# ESP32-C61 register map
Vendor: ESPRESSIF SYSTEMS (SHANGHAI) CO., LTD.; Series: ESP32 C-Series; File version: 1
CPU: RV32IMAC r0p0, little endian, no MPU, no FPU, 0 interrupt priority bits
Address unit: 32 bits
Registers are 32-bit, read-write, reset 0x0 unless marked. A register's access mark holds for its fields unless they carry their own. Offsets are from the block's base; [hi:lo] are bit positions; {n}, {i} and the like mark numbered series.

## AHB_DMA — AHB_DMA Peripheral
Base 0x60080000
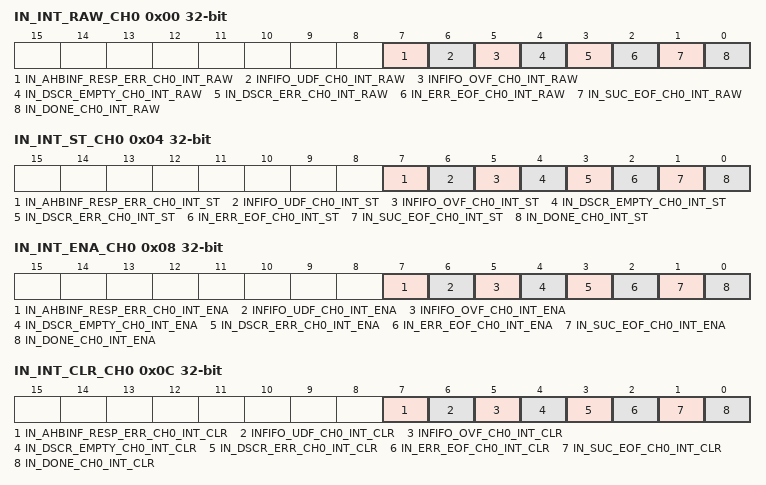
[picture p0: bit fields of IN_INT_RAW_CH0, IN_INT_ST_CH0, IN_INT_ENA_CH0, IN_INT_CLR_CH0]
0x00 IN_INT_RAW_CH0 — Raw interrupt status of RX channel 0
  [7] IN_AHBINF_RESP_ERR_CH0_INT_RAW — The raw interrupt status of AHB_DMA_IN_RESP_ERR_CH0_INT
  [6] INFIFO_UDF_CH0_INT_RAW — The raw interrupt status of AHB_DMA_INFIFO_UDF_CH0_INT
  [5] INFIFO_OVF_CH0_INT_RAW — The raw interrupt status of AHB_DMA_INFIFO_OVF_CH0_INT
  [4] IN_DSCR_EMPTY_CH0_INT_RAW — The raw interrupt status of AHB_DMA_IN_DSCR_EMPTY_CH0_INT
  [3] IN_DSCR_ERR_CH0_INT_RAW — The raw interrupt status of AHB_DMA_IN_DSCR_ERR_CH0_INT
  [2] IN_ERR_EOF_CH0_INT_RAW — The raw interrupt status of AHB_DMA_IN_ERR_EOF_CH0_INT
  [1] IN_SUC_EOF_CH0_INT_RAW — The raw interrupt status of AHB_DMA_IN_SUC_EOF_CH0_INT
  [0] IN_DONE_CH0_INT_RAW — The raw interrupt status of AHB_DMA_IN_DONE_CH0_INT
0x04 IN_INT_ST_CH0 ro — Masked interrupt status of RX channel 0
  [7] IN_AHBINF_RESP_ERR_CH0_INT_ST — The masked interrupt status of AHB_DMA_IN_RESP_ERR_CH0_INT
  [6] INFIFO_UDF_CH0_INT_ST — The masked interrupt status of AHB_DMA_INFIFO_UDF_CH0_INT
  [5] INFIFO_OVF_CH0_INT_ST — The masked interrupt status of AHB_DMA_INFIFO_OVF_CH0_INT
  [4] IN_DSCR_EMPTY_CH0_INT_ST — The masked interrupt status of AHB_DMA_IN_DSCR_EMPTY_CH0_INT
  [3] IN_DSCR_ERR_CH0_INT_ST — The masked interrupt status of AHB_DMA_IN_DSCR_ERR_CH0_INT
  [2] IN_ERR_EOF_CH0_INT_ST — The masked interrupt status of AHB_DMA_IN_ERR_EOF_CH0_INT
  [1] IN_SUC_EOF_CH0_INT_ST — The masked interrupt status of AHB_DMA_IN_SUC_EOF_CH0_INT
  [0] IN_DONE_CH0_INT_ST — The masked interrupt status of AHB_DMA_IN_DONE_CH0_INT
0x08 IN_INT_ENA_CH0 — Interrupt enable bits of RX channel 0
  [7] IN_AHBINF_RESP_ERR_CH0_INT_ENA — Write 1 to enable AHB_DMA_IN_RESP_ERR_CH0_INT
  [6] INFIFO_UDF_CH0_INT_ENA — Write 1 to enable AHB_DMA_INFIFO_UDF_CH0_INT
  [5] INFIFO_OVF_CH0_INT_ENA — Write 1 to enable AHB_DMA_INFIFO_OVF_CH0_INT
  [4] IN_DSCR_EMPTY_CH0_INT_ENA — Write 1 to enable AHB_DMA_IN_DSCR_EMPTY_CH0_INT
  [3] IN_DSCR_ERR_CH0_INT_ENA — Write 1 to enable AHB_DMA_IN_DSCR_ERR_CH0_INT
  [2] IN_ERR_EOF_CH0_INT_ENA — Write 1 to enable AHB_DMA_IN_ERR_EOF_CH0_INT
  [1] IN_SUC_EOF_CH0_INT_ENA — Write 1 to enable AHB_DMA_IN_SUC_EOF_CH0_INT
  [0] IN_DONE_CH0_INT_ENA — Write 1 to enable AHB_DMA_IN_DONE_CH0_INT
0x0C IN_INT_CLR_CH0 wo — Interrupt clear bits of RX channel 0
  [7] IN_AHBINF_RESP_ERR_CH0_INT_CLR — Write 1 to clear AHB_DMA_IN_RESP_ERR_CH0_INT
  [6] INFIFO_UDF_CH0_INT_CLR — Write 1 to clear AHB_DMA_INFIFO_UDF_CH0_INT
  [5] INFIFO_OVF_CH0_INT_CLR — Write 1 to clear AHB_DMA_INFIFO_OVF_CH0_INT
  [4] IN_DSCR_EMPTY_CH0_INT_CLR — Write 1 to clear AHB_DMA_IN_DSCR_EMPTY_CH0_INT
  [3] IN_DSCR_ERR_CH0_INT_CLR — Write 1 to clear AHB_DMA_IN_DSCR_ERR_CH0_INT
  [2] IN_ERR_EOF_CH0_INT_CLR — Write 1 to clear AHB_DMA_IN_ERR_EOF_CH0_INT
  [1] IN_SUC_EOF_CH0_INT_CLR — Write 1 to clear AHB_DMA_IN_SUC_EOF_CH0_INT
  [0] IN_DONE_CH0_INT_CLR — Write 1 to clear AHB_DMA_IN_DONE_CH0_INT
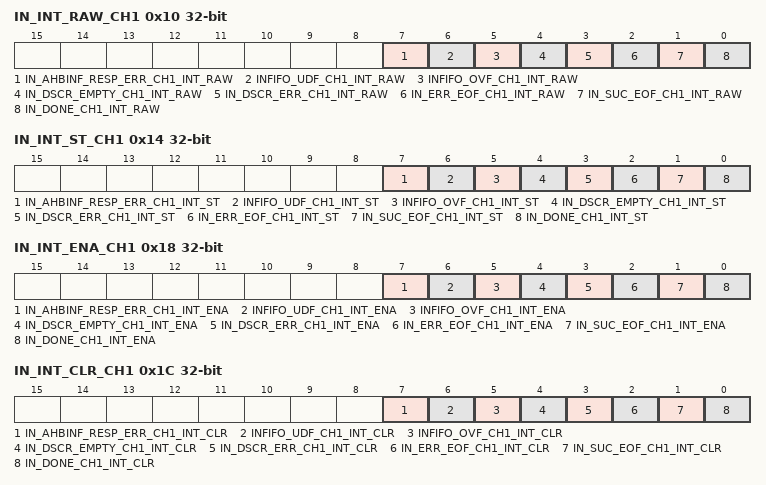
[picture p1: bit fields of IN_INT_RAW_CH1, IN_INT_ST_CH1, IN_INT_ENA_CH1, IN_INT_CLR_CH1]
0x10 IN_INT_RAW_CH1 — Raw interrupt status of RX channel 1
  [7] IN_AHBINF_RESP_ERR_CH1_INT_RAW — The raw interrupt status of AHB_DMA_IN_RESP_ERR_CH1_INT
  [6] INFIFO_UDF_CH1_INT_RAW — The raw interrupt status of AHB_DMA_INFIFO_UDF_CH1_INT
  [5] INFIFO_OVF_CH1_INT_RAW — The raw interrupt status of AHB_DMA_INFIFO_OVF_CH1_INT
  [4] IN_DSCR_EMPTY_CH1_INT_RAW — The raw interrupt status of AHB_DMA_IN_DSCR_EMPTY_CH1_INT
  [3] IN_DSCR_ERR_CH1_INT_RAW — The raw interrupt status of AHB_DMA_IN_DSCR_ERR_CH1_INT
  [2] IN_ERR_EOF_CH1_INT_RAW — The raw interrupt status of AHB_DMA_IN_ERR_EOF_CH1_INT
  [1] IN_SUC_EOF_CH1_INT_RAW — The raw interrupt status of AHB_DMA_IN_SUC_EOF_CH1_INT
  [0] IN_DONE_CH1_INT_RAW — The raw interrupt status of AHB_DMA_IN_DONE_CH1_INT
0x14 IN_INT_ST_CH1 ro — Masked interrupt status of RX channel 1
  [7] IN_AHBINF_RESP_ERR_CH1_INT_ST — The masked interrupt status of AHB_DMA_IN_RESP_ERR_CH1_INT
  [6] INFIFO_UDF_CH1_INT_ST — The masked interrupt status of AHB_DMA_INFIFO_UDF_CH1_INT
  [5] INFIFO_OVF_CH1_INT_ST — The masked interrupt status of AHB_DMA_INFIFO_OVF_CH1_INT
  [4] IN_DSCR_EMPTY_CH1_INT_ST — The masked interrupt status of AHB_DMA_IN_DSCR_EMPTY_CH1_INT
  [3] IN_DSCR_ERR_CH1_INT_ST — The masked interrupt status of AHB_DMA_IN_DSCR_ERR_CH1_INT
  [2] IN_ERR_EOF_CH1_INT_ST — The masked interrupt status of AHB_DMA_IN_ERR_EOF_CH1_INT
  [1] IN_SUC_EOF_CH1_INT_ST — The masked interrupt status of AHB_DMA_IN_SUC_EOF_CH1_INT
  [0] IN_DONE_CH1_INT_ST — The masked interrupt status of AHB_DMA_IN_DONE_CH1_INT
0x18 IN_INT_ENA_CH1 — Interrupt enable bits of RX channel 1
  [7] IN_AHBINF_RESP_ERR_CH1_INT_ENA — Write 1 to enable AHB_DMA_IN_RESP_ERR_CH1_INT
  [6] INFIFO_UDF_CH1_INT_ENA — Write 1 to enable AHB_DMA_INFIFO_UDF_CH1_INT
  [5] INFIFO_OVF_CH1_INT_ENA — Write 1 to enable AHB_DMA_INFIFO_OVF_CH1_INT
  [4] IN_DSCR_EMPTY_CH1_INT_ENA — Write 1 to enable AHB_DMA_IN_DSCR_EMPTY_CH1_INT
  [3] IN_DSCR_ERR_CH1_INT_ENA — Write 1 to enable AHB_DMA_IN_DSCR_ERR_CH1_INT
  [2] IN_ERR_EOF_CH1_INT_ENA — Write 1 to enable AHB_DMA_IN_ERR_EOF_CH1_INT
  [1] IN_SUC_EOF_CH1_INT_ENA — Write 1 to enable AHB_DMA_IN_SUC_EOF_CH1_INT
  [0] IN_DONE_CH1_INT_ENA — Write 1 to enable AHB_DMA_IN_DONE_CH1_INT
0x1C IN_INT_CLR_CH1 wo — Interrupt clear bits of RX channel 1
  [7] IN_AHBINF_RESP_ERR_CH1_INT_CLR — Write 1 to clear AHB_DMA_IN_RESP_ERR_CH1_INT
  [6] INFIFO_UDF_CH1_INT_CLR — Write 1 to clear AHB_DMA_INFIFO_UDF_CH1_INT
  [5] INFIFO_OVF_CH1_INT_CLR — Write 1 to clear AHB_DMA_INFIFO_OVF_CH1_INT
  [4] IN_DSCR_EMPTY_CH1_INT_CLR — Write 1 to clear AHB_DMA_IN_DSCR_EMPTY_CH1_INT
  [3] IN_DSCR_ERR_CH1_INT_CLR — Write 1 to clear AHB_DMA_IN_DSCR_ERR_CH1_INT
  [2] IN_ERR_EOF_CH1_INT_CLR — Write 1 to clear AHB_DMA_IN_ERR_EOF_CH1_INT
  [1] IN_SUC_EOF_CH1_INT_CLR — Write 1 to clear AHB_DMA_IN_SUC_EOF_CH1_INT
  [0] IN_DONE_CH1_INT_CLR — Write 1 to clear AHB_DMA_IN_DONE_CH1_INT
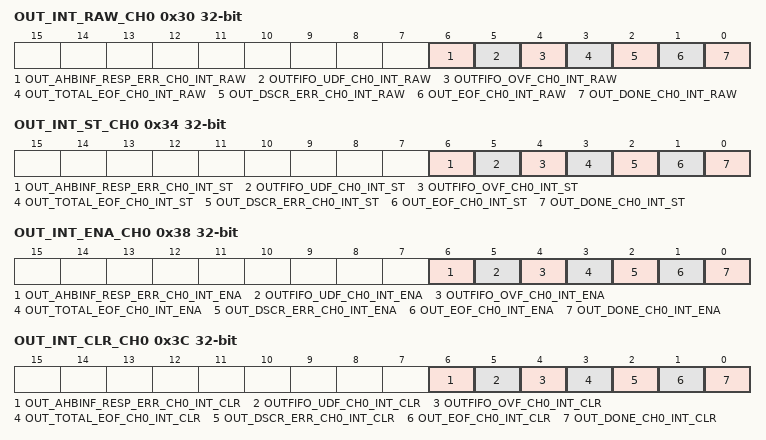
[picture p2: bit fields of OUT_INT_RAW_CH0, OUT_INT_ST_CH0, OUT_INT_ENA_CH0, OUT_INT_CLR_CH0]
0x30 OUT_INT_RAW_CH0 — //Raw interrupt status of TX channel 0
  [6] OUT_AHBINF_RESP_ERR_CH0_INT_RAW — The raw interrupt status of AHB_DMA_OUT_RESP_ERR_CH0_INT
  [5] OUTFIFO_UDF_CH0_INT_RAW — The raw interrupt status of AHB_DMA_OUTFIFO_UDF_CH0_INT
  [4] OUTFIFO_OVF_CH0_INT_RAW — The raw interrupt status of AHB_DMA_OUTFIFO_OVF_CH0_INT
  [3] OUT_TOTAL_EOF_CH0_INT_RAW — The raw interrupt status of AHB_DMA_OUT_TOTAL_EOF_CH0_INT
  [2] OUT_DSCR_ERR_CH0_INT_RAW — The raw interrupt status of AHB_DMA_OUT_DSCR_ERR_CH0_INT
  [1] OUT_EOF_CH0_INT_RAW — The raw interrupt status of AHB_DMA_OUT_EOF_CH0_INT
  [0] OUT_DONE_CH0_INT_RAW — The raw interrupt status of AHB_DMA_OUT_DONE_CH0_INT
0x34 OUT_INT_ST_CH0 ro — Masked interrupt status of TX channel 0
  [6] OUT_AHBINF_RESP_ERR_CH0_INT_ST — The masked interrupt status of AHB_DMA_OUT_RESP_ERR_CH0_INT
  [5] OUTFIFO_UDF_CH0_INT_ST — The masked interrupt status of AHB_DMA_OUTFIFO_UDF_CH0_INT
  [4] OUTFIFO_OVF_CH0_INT_ST — The masked interrupt status of AHB_DMA_OUTFIFO_OVF_CH0_INT
  [3] OUT_TOTAL_EOF_CH0_INT_ST — The masked interrupt status of AHB_DMA_OUT_TOTAL_EOF_CH0_INT
  [2] OUT_DSCR_ERR_CH0_INT_ST — The masked interrupt status of AHB_DMA_OUT_DSCR_ERR_CH0_INT
  [1] OUT_EOF_CH0_INT_ST — The masked interrupt status of AHB_DMA_OUT_EOF_CH0_INT
  [0] OUT_DONE_CH0_INT_ST — The masked interrupt status of AHB_DMA_OUT_DONE_CH0_INT
0x38 OUT_INT_ENA_CH0 — Interrupt enable bits of TX channel 0
  [6] OUT_AHBINF_RESP_ERR_CH0_INT_ENA — Write 1 to enable AHB_DMA_OUT_RESP_ERR_CH0_INT
  [5] OUTFIFO_UDF_CH0_INT_ENA — Write 1 to enable AHB_DMA_OUTFIFO_UDF_CH0_INT
  [4] OUTFIFO_OVF_CH0_INT_ENA — Write 1 to enable AHB_DMA_OUTFIFO_OVF_CH0_INT
  [3] OUT_TOTAL_EOF_CH0_INT_ENA — Write 1 to enable AHB_DMA_OUT_TOTAL_EOF_CH0_INT
  [2] OUT_DSCR_ERR_CH0_INT_ENA — Write 1 to enable AHB_DMA_OUT_DSCR_ERR_CH0_INT
  [1] OUT_EOF_CH0_INT_ENA — Write 1 to enable AHB_DMA_OUT_EOF_CH0_INT
  [0] OUT_DONE_CH0_INT_ENA — Write 1 to enable AHB_DMA_OUT_DONE_CH0_INT
0x3C OUT_INT_CLR_CH0 wo — Interrupt clear bits of TX channel 0
  [6] OUT_AHBINF_RESP_ERR_CH0_INT_CLR — Write 1 to clear AHB_DMA_OUT_RESP_ERR_CH0_INT
  [5] OUTFIFO_UDF_CH0_INT_CLR — Write 1 to clear AHB_DMA_OUTFIFO_UDF_CH0_INT
  [4] OUTFIFO_OVF_CH0_INT_CLR — Write 1 to clear AHB_DMA_OUTFIFO_OVF_CH0_INT
  [3] OUT_TOTAL_EOF_CH0_INT_CLR — Write 1 to clear AHB_DMA_OUT_TOTAL_EOF_CH0_INT
  [2] OUT_DSCR_ERR_CH0_INT_CLR — Write 1 to clear AHB_DMA_OUT_DSCR_ERR_CH0_INT
  [1] OUT_EOF_CH0_INT_CLR — Write 1 to clear AHB_DMA_OUT_EOF_CH0_INT
  [0] OUT_DONE_CH0_INT_CLR — Write 1 to clear AHB_DMA_OUT_DONE_CH0_INT
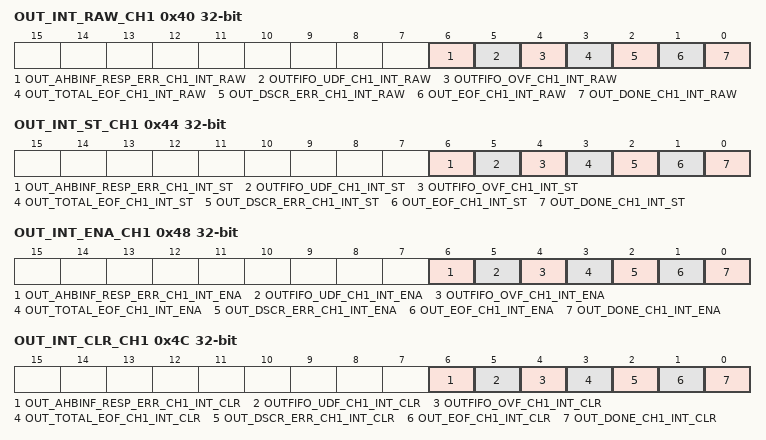
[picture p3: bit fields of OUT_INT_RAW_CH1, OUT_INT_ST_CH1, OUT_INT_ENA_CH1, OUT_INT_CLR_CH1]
0x40 OUT_INT_RAW_CH1 — //Raw interrupt status of TX channel 1
  [6] OUT_AHBINF_RESP_ERR_CH1_INT_RAW — The raw interrupt status of AHB_DMA_OUT_RESP_ERR_CH1_INT
  [5] OUTFIFO_UDF_CH1_INT_RAW — The raw interrupt status of AHB_DMA_OUTFIFO_UDF_CH1_INT
  [4] OUTFIFO_OVF_CH1_INT_RAW — The raw interrupt status of AHB_DMA_OUTFIFO_OVF_CH1_INT
  [3] OUT_TOTAL_EOF_CH1_INT_RAW — The raw interrupt status of AHB_DMA_OUT_TOTAL_EOF_CH1_INT
  [2] OUT_DSCR_ERR_CH1_INT_RAW — The raw interrupt status of AHB_DMA_OUT_DSCR_ERR_CH1_INT
  [1] OUT_EOF_CH1_INT_RAW — The raw interrupt status of AHB_DMA_OUT_EOF_CH1_INT
  [0] OUT_DONE_CH1_INT_RAW — The raw interrupt status of AHB_DMA_OUT_DONE_CH1_INT
0x44 OUT_INT_ST_CH1 ro — Masked interrupt status of TX channel 1
  [6] OUT_AHBINF_RESP_ERR_CH1_INT_ST — The masked interrupt status of AHB_DMA_OUT_RESP_ERR_CH1_INT
  [5] OUTFIFO_UDF_CH1_INT_ST — The masked interrupt status of AHB_DMA_OUTFIFO_UDF_CH1_INT
  [4] OUTFIFO_OVF_CH1_INT_ST — The masked interrupt status of AHB_DMA_OUTFIFO_OVF_CH1_INT
  [3] OUT_TOTAL_EOF_CH1_INT_ST — The masked interrupt status of AHB_DMA_OUT_TOTAL_EOF_CH1_INT
  [2] OUT_DSCR_ERR_CH1_INT_ST — The masked interrupt status of AHB_DMA_OUT_DSCR_ERR_CH1_INT
  [1] OUT_EOF_CH1_INT_ST — The masked interrupt status of AHB_DMA_OUT_EOF_CH1_INT
  [0] OUT_DONE_CH1_INT_ST — The masked interrupt status of AHB_DMA_OUT_DONE_CH1_INT
0x48 OUT_INT_ENA_CH1 — Interrupt enable bits of TX channel 1
  [6] OUT_AHBINF_RESP_ERR_CH1_INT_ENA — Write 1 to enable AHB_DMA_OUT_RESP_ERR_CH1_INT
  [5] OUTFIFO_UDF_CH1_INT_ENA — Write 1 to enable AHB_DMA_OUTFIFO_UDF_CH1_INT
  [4] OUTFIFO_OVF_CH1_INT_ENA — Write 1 to enable AHB_DMA_OUTFIFO_OVF_CH1_INT
  [3] OUT_TOTAL_EOF_CH1_INT_ENA — Write 1 to enable AHB_DMA_OUT_TOTAL_EOF_CH1_INT
  [2] OUT_DSCR_ERR_CH1_INT_ENA — Write 1 to enable AHB_DMA_OUT_DSCR_ERR_CH1_INT
  [1] OUT_EOF_CH1_INT_ENA — Write 1 to enable AHB_DMA_OUT_EOF_CH1_INT
  [0] OUT_DONE_CH1_INT_ENA — Write 1 to enable AHB_DMA_OUT_DONE_CH1_INT
0x4C OUT_INT_CLR_CH1 wo — Interrupt clear bits of TX channel 1
  [6] OUT_AHBINF_RESP_ERR_CH1_INT_CLR — Write 1 to clear AHB_DMA_OUT_RESP_ERR_CH1_INT
  [5] OUTFIFO_UDF_CH1_INT_CLR — Write 1 to clear AHB_DMA_OUTFIFO_UDF_CH1_INT
  [4] OUTFIFO_OVF_CH1_INT_CLR — Write 1 to clear AHB_DMA_OUTFIFO_OVF_CH1_INT
  [3] OUT_TOTAL_EOF_CH1_INT_CLR — Write 1 to clear AHB_DMA_OUT_TOTAL_EOF_CH1_INT
  [2] OUT_DSCR_ERR_CH1_INT_CLR — Write 1 to clear AHB_DMA_OUT_DSCR_ERR_CH1_INT
  [1] OUT_EOF_CH1_INT_CLR — Write 1 to clear AHB_DMA_OUT_EOF_CH1_INT
  [0] OUT_DONE_CH1_INT_CLR — Write 1 to clear AHB_DMA_OUT_DONE_CH1_INT
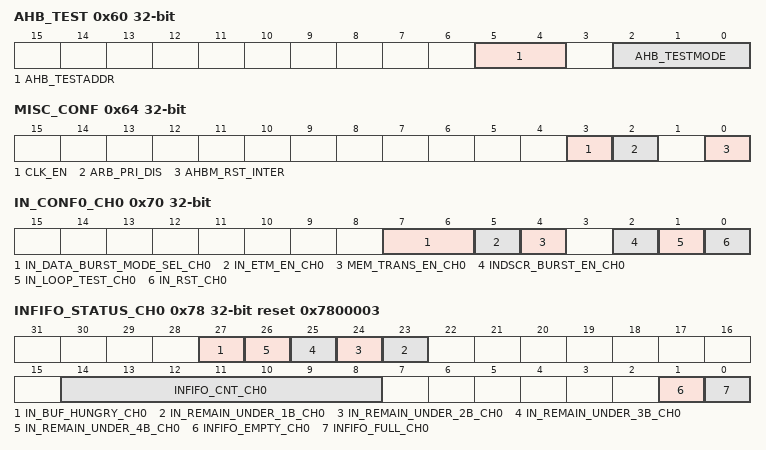
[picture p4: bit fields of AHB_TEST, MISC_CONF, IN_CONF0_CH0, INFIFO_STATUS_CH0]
0x60 AHB_TEST — only for test
  [5:4] AHB_TESTADDR — reserved
  [2:0] AHB_TESTMODE — reserved
0x64 MISC_CONF — reserved
  [3] CLK_EN — Configures clock gating.\\0: Support clock only when the application writes registers.\\ 1: Always force the clock on for registers.\\
  [2] ARB_PRI_DIS — Configures whether to disable the fixed-priority channel arbitration.\\0: Enable\\1: Disable\\
  [0] AHBM_RST_INTER — Write 1 and then 0 to reset the internal AHB FSM
0x68 DATE reset 0x24C6EC — Version control register
0x70 IN_CONF0_CH0 — Configuration register 0 of RX channel 0
  [7:6] IN_DATA_BURST_MODE_SEL_CH0 — Configures max burst size for Rx channel0.\\2'b00: single\\ 2'b01: incr4\\ 2'b10: incr8\\ 2'b11: incr16\\
  [5] IN_ETM_EN_CH0 — Configures whether to enable ETM control for RX channel0.\\0: Disable\\1: Enable\\
  [4] MEM_TRANS_EN_CH0 — Configures whether to enable memory-to-memory data transfer.\\0: Disable\\1: Enable\\
  [2] INDSCR_BURST_EN_CH0 — Configures whether to enable INCR burst transfer for RX channel 0 to read descriptors.\\0: Disable\\1: Enable\\
  [1] IN_LOOP_TEST_CH0 — reserved
  [0] IN_RST_CH0 — Write 1 and then 0 to reset AHB_DMA channel 0 RX FSM and RX FIFO pointer.
0x74 IN_CONF1_CH0 — Configuration register 1 of RX channel 0
  [12] IN_CHECK_OWNER_CH0 — Configures whether to enable owner bit check for RX channel 0.\\0: Disable\\1: Enable\\
0x78 INFIFO_STATUS_CH0 ro reset 0x7800003 — Receive FIFO status of RX channel 0
  [27] IN_BUF_HUNGRY_CH0 — reserved
  [n+22] IN_REMAIN_UNDER_{n}B_CH0 (n=1..4) — reserved
  [14:8] INFIFO_CNT_CH0 — Represents the number of data bytes in L1 RX FIFO for RX channel 0
  [1] INFIFO_EMPTY_CH0 — Represents whether L1 RX FIFO is empty.\\0: Not empty\\1: Empty\\
  [0] INFIFO_FULL_CH0 — Represents whether L1 RX FIFO is full.\\0: Not Full\\1: Full\\
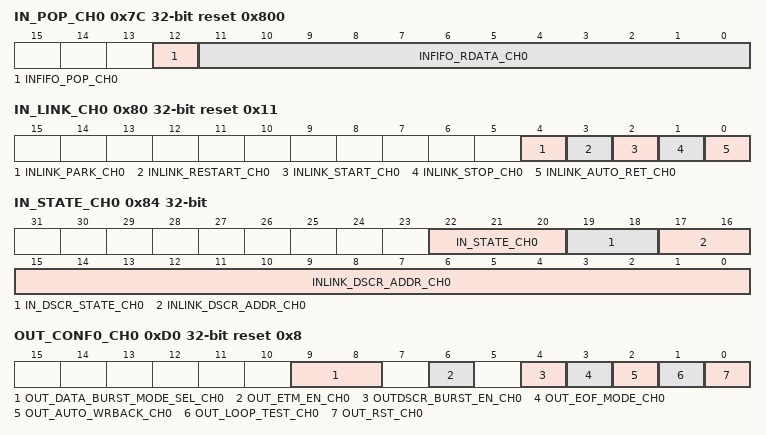
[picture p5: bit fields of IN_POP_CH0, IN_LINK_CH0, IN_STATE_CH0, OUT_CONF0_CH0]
0x7C IN_POP_CH0 access per field reset 0x800 — Receive FIFO status of RX channel 0
  [12] INFIFO_POP_CH0 wo — Configures whether to pop data from AHB_DMA FIFO.\\0: Invalid. No effect\\1: Pop\\
  [11:0] INFIFO_RDATA_CH0 ro — Represents the data popped from AHB_DMA FIFO.
0x80 IN_LINK_CH0 access per field reset 0x11 — Receive FIFO status of RX channel 0
  [4] INLINK_PARK_CH0 ro — Represents the status of the receive descriptor's FSM.\\0: Running\\1: Idle\\
  [3] INLINK_RESTART_CH0 wo — Configures whether to restart RX channel 0 for AHB_DMA transfer.\\0: Invalid. No effect\\1: Restart\\
  [2] INLINK_START_CH0 wo — Configures whether to enable AHB_DMA's RX channel 0 for data transfer.\\0: Disable\\1: Enable\\
  [1] INLINK_STOP_CH0 wo — Configures whether to stop AHB_DMA's RX channel 0 from receiving data.\\0: Invalid. No effect\\1: Stop\\
  [0] INLINK_AUTO_RET_CH0 rw — Configures whether to return to current receive descriptor's address when there are some errors in current receiving data.\\0: Not return\\1: Return\\.
0x84 IN_STATE_CH0 ro — Receive status of RX channel 0
  [22:20] IN_STATE_CH0 — Represents the address of the lower 18 bits of the next receive descriptor to be processed.
  [19:18] IN_DSCR_STATE_CH0 — reserved
  [17:0] INLINK_DSCR_ADDR_CH0 — reserved
0x88 IN_SUC_EOF_DES_ADDR_CH0 ro — Receive descriptor address when EOF occurs on RX channel 0
  [31:0] IN_SUC_EOF_DES_ADDR_CH0 — Represents the address of the receive descriptor when the EOF bit in this descriptor is 1.
0x8C IN_ERR_EOF_DES_ADDR_CH0 ro — Receive descriptor address when errors occur of RX channel 0
  [31:0] IN_ERR_EOF_DES_ADDR_CH0 — Represents the address of the receive descriptor when there are some errors in the currently received data.
0x90 IN_DSCR_CH0 ro — Current receive descriptor address of RX channel 0
  [31:0] INLINK_DSCR_CH0 — Represents the address of the next receive descriptor x+1 pointed by the current receive descriptor that has already been fetched.
0x94 IN_DSCR_BF0_CH0 ro — The last receive descriptor address of RX channel 0
  [31:0] INLINK_DSCR_BF0_CH0 — Represents the address of the current receive descriptor x that has already been fetched.
0x98 IN_DSCR_BF1_CH0 ro — The second-to-last receive descriptor address of RX channel 0
  [31:0] INLINK_DSCR_BF1_CH0 — Represents the address of the previous receive descriptor x-1 that has already been fetched.
0x9C IN_PRI_CH0 — Priority register of RX channel 0
  [3:0] RX_PRI_CH0 — Configures the priority of RX channel 0.The larger of the value, the higher of the priority..
0xA0 IN_PERI_SEL_CH0 reset 0x3F — Peripheral selection register of RX channel 0
  [5:0] PERI_IN_SEL_CH0 — Configures the peripheral connected to RX channel 0.\\ 0: Dummy\\ 1: SPI2\\ 2: UHCI0\\ 3: I2S0\\ 4: Dummy\\ 5: Dummy\\ 6: AES\\ 7: SHA\\ 8: ADC_DAC\\ 9: PARL_IO\\ 10: Dummy\\ 11~15: Dummy\\
0xB0 IN_DONE_DES_ADDR_CH0 ro — RX_done Inlink descriptor address of RX channel 0
  [31:0] IN_DONE_DES_ADDR_CH0 — Represents the address of the inlink descriptor when this descriptor is completed .
0xD0 OUT_CONF0_CH0 reset 0x8 — Configuration register 0 of TX channel 0
  [9:8] OUT_DATA_BURST_MODE_SEL_CH0 — Configures max burst size for TX channel0.\\2'b00: single\\ 2'b01: incr4\\ 2'b10: incr8\\ 2'b11: incr16\\
  [6] OUT_ETM_EN_CH0 — Configures whether to enable ETM control for TX channel 0.\\0: Disable\\1: Enable\\
  [4] OUTDSCR_BURST_EN_CH0 — Configures whether to enable INCR burst transfer for TX channel 0 reading descriptors.\\0: Disable\\1: Enable\\
  [3] OUT_EOF_MODE_CH0 — Configures when to generate EOF flag.\\0: EOF flag for TX channel 0 is generated when data to be transmitted has been pushed into FIFO in AHB_DMA.\\ 1: EOF flag for TX channel 0 is generated when data to be transmitted has been popped from FIFO in AHB_DMA.\\
  [2] OUT_AUTO_WRBACK_CH0 — Configures whether to enable automatic outlink write-back when all the data in TX FIFO has been transmitted.\\0: Disable\\1: Enable\\
  [1] OUT_LOOP_TEST_CH0 — reserved
  [0] OUT_RST_CH0 — Configures the reset state of AHB_DMA channel 0 TX FSM and TX FIFO pointer.\\0: Release reset\\1: Reset\\
0xD4 OUT_CONF1_CH0 — Configuration register 1 of TX channel 0
  [12] OUT_CHECK_OWNER_CH0 — Configures whether to enable owner bit check for TX channel 0.\\0: Disable\\1: Enable\\
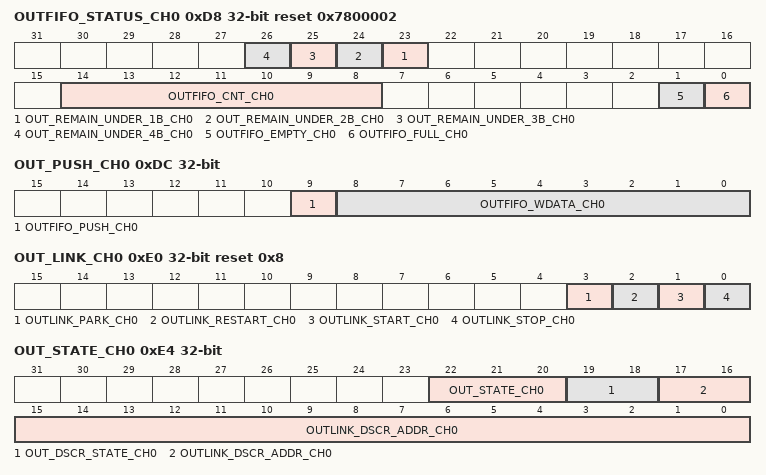
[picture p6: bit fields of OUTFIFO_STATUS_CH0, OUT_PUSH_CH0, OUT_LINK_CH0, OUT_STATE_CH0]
0xD8 OUTFIFO_STATUS_CH0 ro reset 0x7800002 — Receive FIFO status of RX channel 0
  [n+22] OUT_REMAIN_UNDER_{n}B_CH0 (n=1..4) — reserved
  [14:8] OUTFIFO_CNT_CH0 — Represents the number of data bytes in L1 TX FIFO for TX channel 0
  [1] OUTFIFO_EMPTY_CH0 — Represents whether L1 TX FIFO is empty.\\0: Not empty\\1: Empty\\
  [0] OUTFIFO_FULL_CH0 — Represents whether L1 TX FIFO is full.\\0: Not Full\\1: Full\\
0xDC OUT_PUSH_CH0 access per field — Push control register of TX channel 0
  [9] OUTFIFO_PUSH_CH0 wo — Configures the data that need to be pushed into AHB_DMA FIFO.
  [8:0] OUTFIFO_WDATA_CH0 rw — Configures whether to push data into AHB_DMA FIFO.\\0: Invalid. No effect\\1: Push\\
0xE0 OUT_LINK_CH0 access per field reset 0x8 — Push control register of TX channel 0
  [3] OUTLINK_PARK_CH0 ro — Represents the status of the transmit descriptor's FSM.\\0: Running\\1: Idle\\
  [2] OUTLINK_RESTART_CH0 wo — Configures whether to restart TX channel 0 for AHB_DMA transfer.\\0: Invalid. No effect\\1: Restart\\
  [1] OUTLINK_START_CH0 wo — Configures whether to enable AHB_DMA's TX channel 0 for data transfer.\\0: Disable\\1: Enable\\
  [0] OUTLINK_STOP_CH0 wo — Configures whether to stop AHB_DMA's TX channel 0 from transmitting data.\\0: Invalid. No effect\\1: Stop\\
0xE4 OUT_STATE_CH0 ro — Transmit status of TX channel 0
  [22:20] OUT_STATE_CH0 — reserved
  [19:18] OUT_DSCR_STATE_CH0 — reserved
  [17:0] OUTLINK_DSCR_ADDR_CH0 — Represents the lower 18 bits of the address of the next transmit descriptor to be processed.
0xE8 OUT_EOF_DES_ADDR_CH0 ro — Transmit descriptor address when EOF occurs on TX channel 0
  [31:0] OUT_EOF_DES_ADDR_CH0 — Represents the address of the transmit descriptor when the EOF bit in this descriptor is 1.
0xEC OUT_EOF_BFR_DES_ADDR_CH0 ro — The last transmit descriptor address when EOF occurs on TX channel 0
  [31:0] OUT_EOF_BFR_DES_ADDR_CH0 — Represents the address of the transmit descriptor before the last transmit descriptor.
0xF0 OUT_DSCR_CH0 ro — Current transmit descriptor address of TX channel 0
  [31:0] OUTLINK_DSCR_CH0 — Represents the address of the next transmit descriptor y+1 pointed by the current transmit descriptor that has already been fetched.
0xF4 OUT_DSCR_BF0_CH0 ro — The last transmit descriptor address of TX channel 0
  [31:0] OUTLINK_DSCR_BF0_CH0 — Represents the address of the current transmit descriptor y that has already been fetched.
0xF8 OUT_DSCR_BF1_CH0 ro — The second-to-last transmit descriptor address of TX channel 0
  [31:0] OUTLINK_DSCR_BF1_CH0 — Represents the address of the previous transmit descriptor y-1 that has already been fetched.
0xFC OUT_PRI_CH0 — Priority register of TX channel 0
  [3:0] TX_PRI_CH0 — Configures the priority of TX channel 0.The larger of the value, the higher of the priority..
0x100 OUT_PERI_SEL_CH0 reset 0x3F — Peripheral selection register of TX channel 0
  [5:0] PERI_OUT_SEL_CH0 — Configures the peripheral connected to TX channel 0.\\ 0: Dummy\\ 1: SPI2\\ 2: UHCI0\\ 3: I2S0\\ 4: Dummy\\ 5: Dummy\\ 6: AES\\ 7: SHA\\ 8: ADC_DAC\\ 9: PARL_IO\\ 10: Dummy\\ 11~15: Dummy\\
0x110 OUT_DONE_DES_ADDR_CH0 ro — TX done outlink descriptor address of TX channel 0
  [31:0] OUT_DONE_DES_ADDR_CH0 — Represents the address of the outlink descriptor when this descriptor is completed.
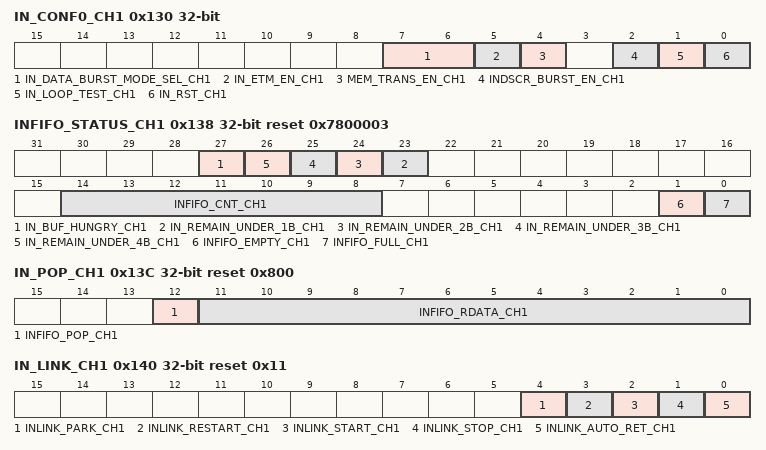
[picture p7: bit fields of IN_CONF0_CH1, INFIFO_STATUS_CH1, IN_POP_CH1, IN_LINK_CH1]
0x130 IN_CONF0_CH1 — Configuration register 0 of RX channel 1
  [7:6] IN_DATA_BURST_MODE_SEL_CH1 — Configures max burst size for Rx channel1.\\2'b00: single\\ 2'b01: incr4\\ 2'b10: incr8\\ 2'b11: incr16\\
  [5] IN_ETM_EN_CH1 — Configures whether to enable ETM control for RX channel1.\\0: Disable\\1: Enable\\
  [4] MEM_TRANS_EN_CH1 — Configures whether to enable memory-to-memory data transfer.\\0: Disable\\1: Enable\\
  [2] INDSCR_BURST_EN_CH1 — Configures whether to enable INCR burst transfer for RX channel 1 to read descriptors.\\0: Disable\\1: Enable\\
  [1] IN_LOOP_TEST_CH1 — reserved
  [0] IN_RST_CH1 — Write 1 and then 0 to reset AHB_DMA channel 1 RX FSM and RX FIFO pointer.
0x134 IN_CONF1_CH1 — Configuration register 1 of RX channel 1
  [12] IN_CHECK_OWNER_CH1 — Configures whether to enable owner bit check for RX channel 1.\\0: Disable\\1: Enable\\
0x138 INFIFO_STATUS_CH1 ro reset 0x7800003 — Receive FIFO status of RX channel 1
  [27] IN_BUF_HUNGRY_CH1 — reserved
  [n+22] IN_REMAIN_UNDER_{n}B_CH1 (n=1..4) — reserved
  [14:8] INFIFO_CNT_CH1 — Represents the number of data bytes in L1 RX FIFO for RX channel 1
  [1] INFIFO_EMPTY_CH1 — Represents whether L1 RX FIFO is empty.\\0: Not empty\\1: Empty\\
  [0] INFIFO_FULL_CH1 — Represents whether L1 RX FIFO is full.\\0: Not Full\\1: Full\\
0x13C IN_POP_CH1 access per field reset 0x800 — Receive FIFO status of RX channel 1
  [12] INFIFO_POP_CH1 wo — Configures whether to pop data from AHB_DMA FIFO.\\0: Invalid. No effect\\1: Pop\\
  [11:0] INFIFO_RDATA_CH1 ro — Represents the data popped from AHB_DMA FIFO.
0x140 IN_LINK_CH1 access per field reset 0x11 — Receive FIFO status of RX channel 1
  [4] INLINK_PARK_CH1 ro — Represents the status of the receive descriptor's FSM.\\0: Running\\1: Idle\\
  [3] INLINK_RESTART_CH1 wo — Configures whether to restart RX channel 1 for AHB_DMA transfer.\\0: Invalid. No effect\\1: Restart\\
  [2] INLINK_START_CH1 wo — Configures whether to enable AHB_DMA's RX channel 1 for data transfer.\\0: Disable\\1: Enable\\
  [1] INLINK_STOP_CH1 wo — Configures whether to stop AHB_DMA's RX channel 1 from receiving data.\\0: Invalid. No effect\\1: Stop\\
  [0] INLINK_AUTO_RET_CH1 rw — Configures whether to return to current receive descriptor's address when there are some errors in current receiving data.\\0: Not return\\1: Return\\.
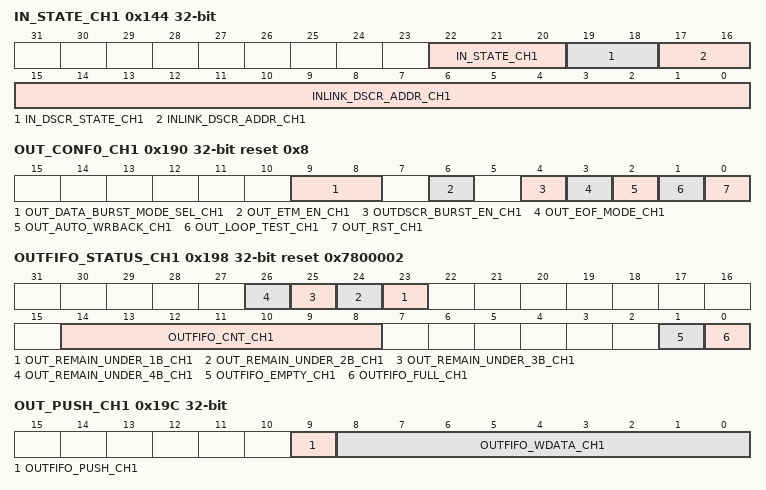
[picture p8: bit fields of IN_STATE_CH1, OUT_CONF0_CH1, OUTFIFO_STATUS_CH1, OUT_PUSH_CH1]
0x144 IN_STATE_CH1 ro — Receive status of RX channel 1
  [22:20] IN_STATE_CH1 — Represents the address of the lower 18 bits of the next receive descriptor to be processed.
  [19:18] IN_DSCR_STATE_CH1 — reserved
  [17:0] INLINK_DSCR_ADDR_CH1 — reserved
0x148 IN_SUC_EOF_DES_ADDR_CH1 ro — Receive descriptor address when EOF occurs on RX channel 1
  [31:0] IN_SUC_EOF_DES_ADDR_CH1 — Represents the address of the receive descriptor when the EOF bit in this descriptor is 1.
0x14C IN_ERR_EOF_DES_ADDR_CH1 ro — Receive descriptor address when errors occur of RX channel 1
  [31:0] IN_ERR_EOF_DES_ADDR_CH1 — Represents the address of the receive descriptor when there are some errors in the currently received data.
0x150 IN_DSCR_CH1 ro — Current receive descriptor address of RX channel 1
  [31:0] INLINK_DSCR_CH1 — Represents the address of the next receive descriptor x+1 pointed by the current receive descriptor that has already been fetched.
0x154 IN_DSCR_BF0_CH1 ro — The last receive descriptor address of RX channel 1
  [31:0] INLINK_DSCR_BF0_CH1 — Represents the address of the current receive descriptor x that has already been fetched.
0x158 IN_DSCR_BF1_CH1 ro — The second-to-last receive descriptor address of RX channel 1
  [31:0] INLINK_DSCR_BF1_CH1 — Represents the address of the previous receive descriptor x-1 that has already been fetched.
0x15C IN_PRI_CH1 — Priority register of RX channel 1
  [3:0] RX_PRI_CH1 — Configures the priority of RX channel 1.The larger of the value, the higher of the priority..
0x160 IN_PERI_SEL_CH1 reset 0x3F — Peripheral selection register of RX channel 1
  [5:0] PERI_IN_SEL_CH1 — Configures the peripheral connected to RX channel 1.\\ 0: Dummy\\ 1: SPI2\\ 2: UHCI0\\ 3: I2S0\\ 4: Dummy\\ 5: Dummy\\ 6: AES\\ 7: SHA\\ 8: ADC_DAC\\ 9: PARL_IO\\ 10: Dummy\\ 11~15: Dummy\\
0x170 IN_DONE_DES_ADDR_CH1 ro — RX_done Inlink descriptor address of RX channel 1
  [31:0] IN_DONE_DES_ADDR_CH1 — Represents the address of the inlink descriptor when this descriptor is completed .
0x190 OUT_CONF0_CH1 reset 0x8 — Configuration register 0 of TX channel 1
  [9:8] OUT_DATA_BURST_MODE_SEL_CH1 — Configures max burst size for TX channel1.\\2'b00: single\\ 2'b01: incr4\\ 2'b10: incr8\\ 2'b11: incr16\\
  [6] OUT_ETM_EN_CH1 — Configures whether to enable ETM control for TX channel 1.\\0: Disable\\1: Enable\\
  [4] OUTDSCR_BURST_EN_CH1 — Configures whether to enable INCR burst transfer for TX channel 1 reading descriptors.\\0: Disable\\1: Enable\\
  [3] OUT_EOF_MODE_CH1 — Configures when to generate EOF flag.\\0: EOF flag for TX channel 1 is generated when data to be transmitted has been pushed into FIFO in AHB_DMA.\\ 1: EOF flag for TX channel 1 is generated when data to be transmitted has been popped from FIFO in AHB_DMA.\\
  [2] OUT_AUTO_WRBACK_CH1 — Configures whether to enable automatic outlink write-back when all the data in TX FIFO has been transmitted.\\0: Disable\\1: Enable\\
  [1] OUT_LOOP_TEST_CH1 — reserved
  [0] OUT_RST_CH1 — Configures the reset state of AHB_DMA channel 1 TX FSM and TX FIFO pointer.\\0: Release reset\\1: Reset\\
0x194 OUT_CONF1_CH1 — Configuration register 1 of TX channel 1
  [12] OUT_CHECK_OWNER_CH1 — Configures whether to enable owner bit check for TX channel 1.\\0: Disable\\1: Enable\\
0x198 OUTFIFO_STATUS_CH1 ro reset 0x7800002 — Receive FIFO status of RX channel 1
  [n+22] OUT_REMAIN_UNDER_{n}B_CH1 (n=1..4) — reserved
  [14:8] OUTFIFO_CNT_CH1 — Represents the number of data bytes in L1 TX FIFO for TX channel 1
  [1] OUTFIFO_EMPTY_CH1 — Represents whether L1 TX FIFO is empty.\\0: Not empty\\1: Empty\\
  [0] OUTFIFO_FULL_CH1 — Represents whether L1 TX FIFO is full.\\0: Not Full\\1: Full\\
0x19C OUT_PUSH_CH1 access per field — Push control register of TX channel 1
  [9] OUTFIFO_PUSH_CH1 wo — Configures the data that need to be pushed into AHB_DMA FIFO.
  [8:0] OUTFIFO_WDATA_CH1 rw — Configures whether to push data into AHB_DMA FIFO.\\0: Invalid. No effect\\1: Push\\
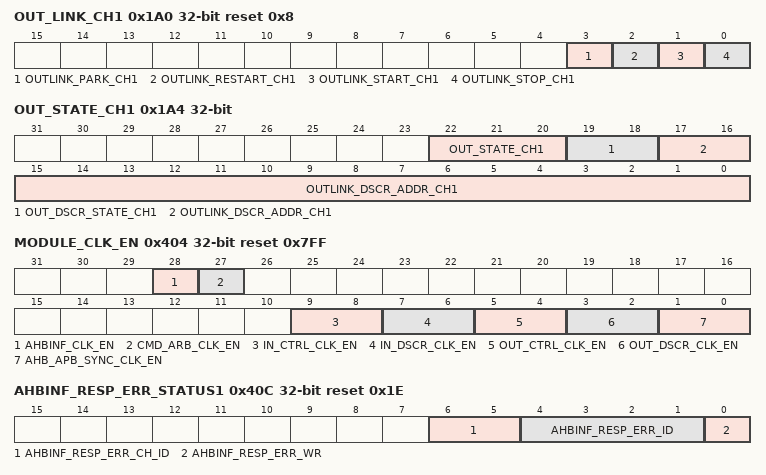
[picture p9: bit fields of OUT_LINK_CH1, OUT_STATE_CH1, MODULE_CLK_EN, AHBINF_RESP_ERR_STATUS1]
0x1A0 OUT_LINK_CH1 access per field reset 0x8 — Push control register of TX channel 1
  [3] OUTLINK_PARK_CH1 ro — Represents the status of the transmit descriptor's FSM.\\0: Running\\1: Idle\\
  [2] OUTLINK_RESTART_CH1 wo — Configures whether to restart TX channel 1 for AHB_DMA transfer.\\0: Invalid. No effect\\1: Restart\\
  [1] OUTLINK_START_CH1 wo — Configures whether to enable AHB_DMA's TX channel 1 for data transfer.\\0: Disable\\1: Enable\\
  [0] OUTLINK_STOP_CH1 wo — Configures whether to stop AHB_DMA's TX channel 1 from transmitting data.\\0: Invalid. No effect\\1: Stop\\
0x1A4 OUT_STATE_CH1 ro — Transmit status of TX channel 1
  [22:20] OUT_STATE_CH1 — reserved
  [19:18] OUT_DSCR_STATE_CH1 — reserved
  [17:0] OUTLINK_DSCR_ADDR_CH1 — Represents the lower 18 bits of the address of the next transmit descriptor to be processed.
0x1A8 OUT_EOF_DES_ADDR_CH1 ro — Transmit descriptor address when EOF occurs on TX channel 1
  [31:0] OUT_EOF_DES_ADDR_CH1 — Represents the address of the transmit descriptor when the EOF bit in this descriptor is 1.
0x1AC OUT_EOF_BFR_DES_ADDR_CH1 ro — The last transmit descriptor address when EOF occurs on TX channel 1
  [31:0] OUT_EOF_BFR_DES_ADDR_CH1 — Represents the address of the transmit descriptor before the last transmit descriptor.
0x1B0 OUT_DSCR_CH1 ro — Current transmit descriptor address of TX channel 1
  [31:0] OUTLINK_DSCR_CH1 — Represents the address of the next transmit descriptor y+1 pointed by the current transmit descriptor that has already been fetched.
0x1B4 OUT_DSCR_BF0_CH1 ro — The last transmit descriptor address of TX channel 1
  [31:0] OUTLINK_DSCR_BF0_CH1 — Represents the address of the current transmit descriptor y that has already been fetched.
0x1B8 OUT_DSCR_BF1_CH1 ro — The second-to-last transmit descriptor address of TX channel 1
  [31:0] OUTLINK_DSCR_BF1_CH1 — Represents the address of the previous transmit descriptor y-1 that has already been fetched.
0x1BC OUT_PRI_CH1 — Priority register of TX channel 1
  [3:0] TX_PRI_CH1 — Configures the priority of TX channel 1.The larger of the value, the higher of the priority..
0x1C0 OUT_PERI_SEL_CH1 reset 0x3F — Peripheral selection register of TX channel 1
  [5:0] PERI_OUT_SEL_CH1 — Configures the peripheral connected to TX channel 1.\\ 0: Dummy\\ 1: SPI2\\ 2: UHCI0\\ 3: I2S0\\ 4: Dummy\\ 5: Dummy\\ 6: AES\\ 7: SHA\\ 8: ADC_DAC\\ 9: PARL_IO\\ 10: Dummy\\ 11~15: Dummy\\
0x1D0 OUT_DONE_DES_ADDR_CH1 ro — TX done outlink descriptor address of TX channel 1
  [31:0] OUT_DONE_DES_ADDR_CH1 — Represents the address of the outlink descriptor when this descriptor is completed.
0x2DC TX_CH_ARB_WEIGHT_CH0 — TX channel 0 arbitration weight configuration register
  [3:0] TX_ARB_WEIGHT_VALUE_CH0 — Configures the weight(i.e the number of tokens) of TX channel0
0x2E0 TX_ARB_WEIGHT_OPT_DIR_CH0 — TX channel 0 weight arbitration optimization enable register
  [0] TX_ARB_WEIGHT_OPT_DIS_CH0 — reserved
0x304 TX_CH_ARB_WEIGHT_CH1 — TX channel 1 arbitration weight configuration register
  [3:0] TX_ARB_WEIGHT_VALUE_CH1 — Configures the weight(i.e the number of tokens) of TX channel1
0x308 TX_ARB_WEIGHT_OPT_DIR_CH1 — TX channel 1 weight arbitration optimization enable register
  [0] TX_ARB_WEIGHT_OPT_DIS_CH1 — reserved
0x354 RX_CH_ARB_WEIGHT_CH0 — RX channel 0 arbitration weight configuration register
  [3:0] RX_ARB_WEIGHT_VALUE_CH0 — Configures the weight(i.e the number of tokens) of RX channel0
0x358 RX_ARB_WEIGHT_OPT_DIR_CH0 — RX channel 0 weight arbitration optimization enable register
  [0] RX_ARB_WEIGHT_OPT_DIS_CH0 — reserved
0x37C RX_CH_ARB_WEIGHT_CH1 — RX channel 1 arbitration weight configuration register
  [3:0] RX_ARB_WEIGHT_VALUE_CH1 — Configures the weight(i.e the number of tokens) of RX channel1
0x380 RX_ARB_WEIGHT_OPT_DIR_CH1 — RX channel 1 weight arbitration optimization enable register
  [0] RX_ARB_WEIGHT_OPT_DIS_CH1 — reserved
0x3AC IN_LINK_ADDR_CH0 — Link list descriptor address configuration of RX channel 0
  [31:0] INLINK_ADDR_CH0 — Configures the 32 bits of the first receive descriptor's address
0x3B0 IN_LINK_ADDR_CH1 — Link list descriptor address configuration of RX channel 1
  [31:0] INLINK_ADDR_CH1 — Configures the 32 bits of the first receive descriptor's address
0x3B8 OUT_LINK_ADDR_CH0 — Link list descriptor address configuration of TX channel 0
  [31:0] OUTLINK_ADDR_CH0 — Configures the 32 bits of the first receive descriptor's address.
0x3BC OUT_LINK_ADDR_CH1 — Link list descriptor address configuration of TX channel 1
  [31:0] OUTLINK_ADDR_CH1 — Configures the 32 bits of the first receive descriptor's address.
0x3C4 INTR_MEM_START_ADDR — Accessible address space start address configuration register
  [31:0] ACCESS_INTR_MEM_START_ADDR
0x3C8 INTR_MEM_END_ADDR reset 0xFFFFFFFF — Accessible address space end address configuration register
  [31:0] ACCESS_INTR_MEM_END_ADDR — Configures the end address of accessible address space.
0x3CC ARB_TIMEOUT_TX — TX arbitration timeout configuration register
  [15:0] ARB_TIMEOUT_TX — Configures the time slot for TX. Measurement unit: AHB bus clock cycle.
0x3D0 ARB_TIMEOUT_RX — RX arbitration timeout configuration register
  [15:0] ARB_TIMEOUT_RX — Configures the time slot for RX. Measurement unit: AHB bus clock cycle.
0x3D4 WEIGHT_EN_TX — TX weight arbitration enable register
  [0] WEIGHT_EN_TX — Configures whether to enable weight arbitration for TX.\\0: Disable\\1: Enable\\
0x3D8 WEIGHT_EN_RX — RX weight arbitration enable register
  [0] WEIGHT_EN_RX — Configures whether to enable weight arbitration for RX.\\0: Disable\\1: Enable\\
0x3DC ARB_TIMEOUT — TX arbitration timeout configuration register
  [15:0] NUM — Configures the time slot. Measurement unit: AHB bus clock cycle.
0x400 WEIGHT_EN — TX weight arbitration enable register
  [0] WEIGHT_EN — Configures whether to enable weight arbitration.\\0: Disable\\1: Enable\\
0x404 MODULE_CLK_EN reset 0x7FF — Module clock force on register
  [28] AHBINF_CLK_EN — Configures whether to force on ahbinf module clock. \\0 : Not force on ahbinf clock \\1 : Force on ahbinf clock\\
  [27] CMD_ARB_CLK_EN — Configures whether to force on cmd_arb module clock. \\0 : Not force on cmd_arb clock \\1 : Force on cmd_arb clock\\
  [9:8] IN_CTRL_CLK_EN — Configures whether to force on in_ctrl 1~0 module clock. For bit n:\\0 : Not force on in_ctrl n clock \\1 : Force on in_ctrl n clock\\
  [7:6] IN_DSCR_CLK_EN — Configures whether to force on in_dscr 1~0 module clock. For bit n:\\0 : Not force on in_dscr n clock \\1 : Force on in_dscr n clock\\
  [5:4] OUT_CTRL_CLK_EN — Configures whether to force on out_ctrl 1~0 module clock. For bit n:\\0 : Not force on out_ctrl n clock \\1 : Force on out_ctrl n clock\\
  [3:2] OUT_DSCR_CLK_EN — Configures whether to force on out_dscr 1~0 module clock. For bit n:\\0 : Not force on out_dscr n clock \\1 : Force on out_dscr n clock\\
  [1:0] AHB_APB_SYNC_CLK_EN — Configures whether to force on ahb_apb_sync 1~0 module clock. For bit n:\\0 : Not force on ahb_apb_sync n clock \\1 : Force on ahb_apb_sync n clock\\
0x408 AHBINF_RESP_ERR_STATUS0 ro — AHB response error status 0 register
  [31:0] AHBINF_RESP_ERR_ADDR — Represents the address of the AHB response error.
0x40C AHBINF_RESP_ERR_STATUS1 ro reset 0x1E — AHB response error status 1 register
  [6:5] AHBINF_RESP_ERR_CH_ID — Represents the AHB response error request channel id.bit[1]=1:TX channel.\\bit[1]=0:RX channel.\\
  [4:1] AHBINF_RESP_ERR_ID — Represents the AHB response error request id.
  [0] AHBINF_RESP_ERR_WR — Represents the AHB response error is write request.

## Notices in the file
Copyright 2025 Espressif Systems (Shanghai) PTE LTD
Licensed under the Apache License, Version 2.0 (the "License");
you may not use this file except in compliance with the License.
You may obtain a copy of the License at
http://www.apache.org/licenses/LICENSE-2.0
Unless required by applicable law or agreed to in writing, software
distributed under the License is distributed on an "AS IS" BASIS,
WITHOUT WARRANTIES OR CONDITIONS OF ANY KIND, either express or implied.
See the License for the specific language governing permissions and
limitations under the License.
